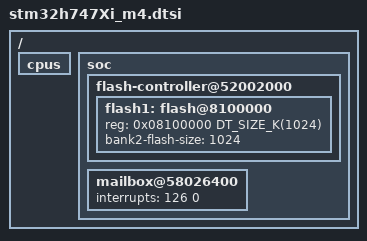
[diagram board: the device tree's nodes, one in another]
/*
 * Copyright (c) 2019 Linaro Limited
 *
 * SPDX-License-Identifier: Apache-2.0
 */

#include <mem.h>
#include <st/h7/stm32h747.dtsi>

/delete-node/ &flash0;

/ {
	cpus {
		/delete-node/ cpu@0;
	};

	soc {
		flash-controller@52002000 {
			flash1: flash@8100000 {
				reg = <0x08100000 DT_SIZE_K(1024)>;
				bank2-flash-size = <1024>;
			};
		};

		mailbox@58026400 {
			interrupts = <126 0>;
		};
	};
};
